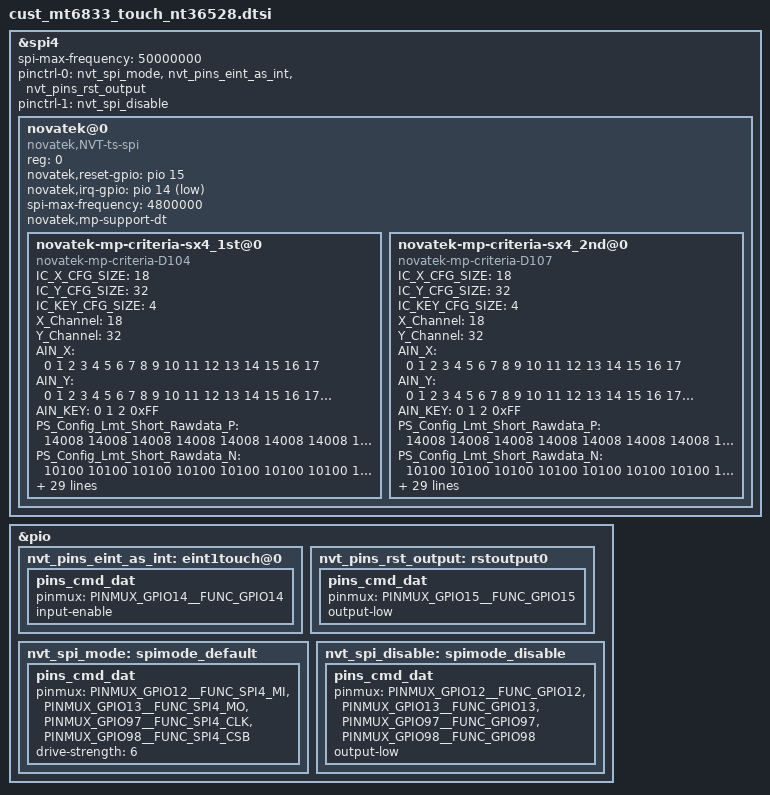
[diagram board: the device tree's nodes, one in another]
&spi4 {
    status = "okay";
	spi-max-frequency = <50000000>;
	pinctrl-names = "nvt_spi_mode", "nvt_spi_disable";
	pinctrl-0 = <&nvt_spi_mode>,<&nvt_pins_eint_as_int>,<&nvt_pins_rst_output>;
	pinctrl-1 = <&nvt_spi_disable>;
	novatek@0 {
        status = "okay";
		compatible = "novatek,NVT-ts-spi";
		reg = <0>; //Same as CS ID
		novatek,reset-gpio = <&pio 15 0x00>;
		novatek,irq-gpio = <&pio 14 0x2001>;	
		spi-max-frequency = <4800000>;	//4800000,9600000,15000000,19200000

		novatek,mp-support-dt;

		novatek-mp-criteria-sx4_1st@0 {
			#address-cells = <1>;
			#size-cells = <0>;
			compatible = "novatek-mp-criteria-D104";

			/* MP Config */
			IC_X_CFG_SIZE = <18>;
			IC_Y_CFG_SIZE = <32>;
			IC_KEY_CFG_SIZE = <4>;
			X_Channel = <18>;
			Y_Channel = <32>;
			AIN_X = <0 1 2 3 4 5 6 7 8 9 10 11 12 13 14 15 16 17>;
			AIN_Y = <0 1 2 3 4 5 6 7 8 9 10 11 12 13 14 15 16 17 18 19 20 21 22 23 24 25 26 27 28 29 30 31>;
			AIN_KEY = <0 1 2 0xFF>;

			/* MP Criteria */
			PS_Config_Lmt_Short_Rawdata_P = <
				14008	14008	14008	14008	14008	14008	14008	14008	14008	14008	14008	14008	14008	14008	14008	14008	14008	14008
				14008	14008	14008	14008	14008	14008	14008	14008	14008	14008	14008	14008	14008	14008	14008	14008	14008	14008
				14008	14008	14008	14008	14008	14008	14008	14008	14008	14008	14008	14008	14008	14008	14008	14008	14008	14008
				14008	14008	14008	14008	14008	14008	14008	14008	14008	14008	14008	14008	14008	14008	14008	14008	14008	14008
				14008	14008	14008	14008	14008	14008	14008	14008	14008	14008	14008	14008	14008	14008	14008	14008	14008	14008
				14008	14008	14008	14008	14008	14008	14008	14008	14008	14008	14008	14008	14008	14008	14008	14008	14008	14008
				14008	14008	14008	14008	14008	14008	14008	14008	14008	14008	14008	14008	14008	14008	14008	14008	14008	14008
				14008	14008	14008	14008	14008	14008	14008	14008	14008	14008	14008	14008	14008	14008	14008	14008	14008	14008
				14008	14008	14008	14008	14008	14008	14008	14008	14008	14008	14008	14008	14008	14008	14008	14008	14008	14008
				14008	14008	14008	14008	14008	14008	14008	14008	14008	14008	14008	14008	14008	14008	14008	14008	14008	14008
				14008	14008	14008	14008	14008	14008	14008	14008	14008	14008	14008	14008	14008	14008	14008	14008	14008	14008
				14008	14008	14008	14008	14008	14008	14008	14008	14008	14008	14008	14008	14008	14008	14008	14008	14008	14008
				14008	14008	14008	14008	14008	14008	14008	14008	14008	14008	14008	14008	14008	14008	14008	14008	14008	14008
				14008	14008	14008	14008	14008	14008	14008	14008	14008	14008	14008	14008	14008	14008	14008	14008	14008	14008
				14008	14008	14008	14008	14008	14008	14008	14008	14008	14008	14008	14008	14008	14008	14008	14008	14008	14008
				14008	14008	14008	14008	14008	14008	14008	14008	14008	14008	14008	14008	14008	14008	14008	14008	14008	14008
				14008	14008	14008	14008	14008	14008	14008	14008	14008	14008	14008	14008	14008	14008	14008	14008	14008	14008
				14008	14008	14008	14008	14008	14008	14008	14008	14008	14008	14008	14008	14008	14008	14008	14008	14008	14008
				14008	14008	14008	14008	14008	14008	14008	14008	14008	14008	14008	14008	14008	14008	14008	14008	14008	14008
				14008	14008	14008	14008	14008	14008	14008	14008	14008	14008	14008	14008	14008	14008	14008	14008	14008	14008
				14008	14008	14008	14008	14008	14008	14008	14008	14008	14008	14008	14008	14008	14008	14008	14008	14008	14008
				14008	14008	14008	14008	14008	14008	14008	14008	14008	14008	14008	14008	14008	14008	14008	14008	14008	14008
				14008	14008	14008	14008	14008	14008	14008	14008	14008	14008	14008	14008	14008	14008	14008	14008	14008	14008
				14008	14008	14008	14008	14008	14008	14008	14008	14008	14008	14008	14008	14008	14008	14008	14008	14008	14008
				14008	14008	14008	14008	14008	14008	14008	14008	14008	14008	14008	14008	14008	14008	14008	14008	14008	14008
				14008	14008	14008	14008	14008	14008	14008	14008	14008	14008	14008	14008	14008	14008	14008	14008	14008	14008
				14008	14008	14008	14008	14008	14008	14008	14008	14008	14008	14008	14008	14008	14008	14008	14008	14008	14008
				14008	14008	14008	14008	14008	14008	14008	14008	14008	14008	14008	14008	14008	14008	14008	14008	14008	14008
				14008	14008	14008	14008	14008	14008	14008	14008	14008	14008	14008	14008	14008	14008	14008	14008	14008	14008
				14008	14008	14008	14008	14008	14008	14008	14008	14008	14008	14008	14008	14008	14008	14008	14008	14008	14008
				14008	14008	14008	14008	14008	14008	14008	14008	14008	14008	14008	14008	14008	14008	14008	14008	14008	14008
				14008	14008	14008	14008	14008	14008	14008	14008	14008	14008	14008	14008	14008	14008	14008	14008	14008	14008
				>;

			PS_Config_Lmt_Short_Rawdata_N = <
				10100	10100	10100	10100	10100	10100	10100	10100	10100	10100	10100	10100	10100	10100	10100	10100	10100	10100
				10100	10100	10100	10100	10100	10100	10100	10100	10100	10100	10100	10100	10100	10100	10100	10100	10100	10100
				10100	10100	10100	10100	10100	10100	10100	10100	10100	10100	10100	10100	10100	10100	10100	10100	10100	10100
				10100	10100	10100	10100	10100	10100	10100	10100	10100	10100	10100	10100	10100	10100	10100	10100	10100	10100
				10100	10100	10100	10100	10100	10100	10100	10100	10100	10100	10100	10100	10100	10100	10100	10100	10100	10100
				10100	10100	10100	10100	10100	10100	10100	10100	10100	10100	10100	10100	10100	10100	10100	10100	10100	10100
				10100	10100	10100	10100	10100	10100	10100	10100	10100	10100	10100	10100	10100	10100	10100	10100	10100	10100
				10100	10100	10100	10100	10100	10100	10100	10100	10100	10100	10100	10100	10100	10100	10100	10100	10100	10100
				10100	10100	10100	10100	10100	10100	10100	10100	10100	10100	10100	10100	10100	10100	10100	10100	10100	10100
				10100	10100	10100	10100	10100	10100	10100	10100	10100	10100	10100	10100	10100	10100	10100	10100	10100	10100
				10100	10100	10100	10100	10100	10100	10100	10100	10100	10100	10100	10100	10100	10100	10100	10100	10100	10100
				10100	10100	10100	10100	10100	10100	10100	10100	10100	10100	10100	10100	10100	10100	10100	10100	10100	10100
				10100	10100	10100	10100	10100	10100	10100	10100	10100	10100	10100	10100	10100	10100	10100	10100	10100	10100
				10100	10100	10100	10100	10100	10100	10100	10100	10100	10100	10100	10100	10100	10100	10100	10100	10100	10100
				10100	10100	10100	10100	10100	10100	10100	10100	10100	10100	10100	10100	10100	10100	10100	10100	10100	10100
				10100	10100	10100	10100	10100	10100	10100	10100	10100	10100	10100	10100	10100	10100	10100	10100	10100	10100
				10100	10100	10100	10100	10100	10100	10100	10100	10100	10100	10100	10100	10100	10100	10100	10100	10100	10100
				10100	10100	10100	10100	10100	10100	10100	10100	10100	10100	10100	10100	10100	10100	10100	10100	10100	10100
				10100	10100	10100	10100	10100	10100	10100	10100	10100	10100	10100	10100	10100	10100	10100	10100	10100	10100
				10100	10100	10100	10100	10100	10100	10100	10100	10100	10100	10100	10100	10100	10100	10100	10100	10100	10100
				10100	10100	10100	10100	10100	10100	10100	10100	10100	10100	10100	10100	10100	10100	10100	10100	10100	10100
				10100	10100	10100	10100	10100	10100	10100	10100	10100	10100	10100	10100	10100	10100	10100	10100	10100	10100
				10100	10100	10100	10100	10100	10100	10100	10100	10100	10100	10100	10100	10100	10100	10100	10100	10100	10100
				10100	10100	10100	10100	10100	10100	10100	10100	10100	10100	10100	10100	10100	10100	10100	10100	10100	10100
				10100	10100	10100	10100	10100	10100	10100	10100	10100	10100	10100	10100	10100	10100	10100	10100	10100	10100
				10100	10100	10100	10100	10100	10100	10100	10100	10100	10100	10100	10100	10100	10100	10100	10100	10100	10100
				10100	10100	10100	10100	10100	10100	10100	10100	10100	10100	10100	10100	10100	10100	10100	10100	10100	10100
				10100	10100	10100	10100	10100	10100	10100	10100	10100	10100	10100	10100	10100	10100	10100	10100	10100	10100
				10100	10100	10100	10100	10100	10100	10100	10100	10100	10100	10100	10100	10100	10100	10100	10100	10100	10100
				10100	10100	10100	10100	10100	10100	10100	10100	10100	10100	10100	10100	10100	10100	10100	10100	10100	10100
				10100	10100	10100	10100	10100	10100	10100	10100	10100	10100	10100	10100	10100	10100	10100	10100	10100	10100
				10100	10100	10100	10100	10100	10100	10100	10100	10100	10100	10100	10100	10100	10100	10100	10100	10100	10100
				>;

			PS_Config_Lmt_Open_Rawdata_P = <
				2667	2643	2563	2510	2446	2381	2345	2269	65535	65535	2043	2113	2132	2184	2230	2248	2302	2356
				2559	2566	2510	2444	2384	2334	2292	2260	2223	2297	2320	2344	2373	2411	2449	2482	2531	2579
				2765	2776	2722	2659	2597	2541	2499	2465	2432	2178	2197	2215	2248	2288	2318	2352	2394	2439
				2600	2625	2572	2507	2446	2394	2352	2318	2289	2342	2360	2383	2418	2456	2492	2530	2575	2618
				2747	2783	2723	2659	2593	2535	2493	2454	2426	2274	2293	2309	2342	2380	2414	2449	2493	2535
				2654	2701	2640	2575	2512	2457	2412	2376	2348	2449	2467	2486	2523	2562	2600	2639	2685	2726
				2773	2740	2694	2638	2568	2507	2475	2432	2393	2302	2327	2356	2379	2426	2465	2492	2533	2482
				2645	2604	2565	2509	2442	2381	2351	2310	2275	2481	2506	2538	2562	2611	2656	2684	2722	2689
				2836	2793	2748	2692	2622	2559	2531	2484	2449	2419	2444	2471	2496	2540	2583	2612	2650	2621
				2709	2663	2621	2565	2498	2437	2407	2363	2331	2541	2566	2597	2622	2667	2712	2747	2782	2768
				2943	2892	2843	2790	2723	2661	2625	2583	2548	2451	2474	2503	2521	2568	2614	2638	2680	2674
				2811	2759	2715	2659	2591	2534	2500	2461	2423	2705	2731	2764	2786	2831	2878	2906	2950	2954
				3031	2976	2927	2867	2803	2740	2702	2664	2619	2570	2591	2625	2643	2692	2736	2758	2801	2814
				2915	2867	2817	2755	2692	2632	2596	2559	2517	2674	2702	2731	2755	2803	2846	2874	2920	2941
				3140	3087	3030	2974	2905	2839	2806	2758	2719	2590	2619	2645	2673	2716	2757	2783	2829	2862
				3011	2960	2908	2849	2780	2722	2685	2643	2605	2766	2793	2821	2852	2895	2939	2975	3017	3058
				3240	3186	3129	3074	3004	2939	2902	2853	2818	2708	2736	2765	2790	2836	2877	2908	2954	3002
				3105	3053	2999	2939	2870	2810	2772	2724	2689	2848	2874	2908	2937	2982	3028	3062	3105	3153
				3342	3297	3241	3177	3109	3046	3002	2960	2915	2757	2775	2813	2835	2883	2927	2955	3000	3045
				3227	3177	3123	3059	2990	2934	2891	2853	2810	2948	2976	3007	3038	3083	3132	3161	3213	3269
				3455	3405	3345	3283	3207	3147	3102	3058	3009	2887	2915	2944	2975	3023	3066	3094	3144	3200
				3331	3282	3228	3161	3090	3024	2985	2939	2895	3083	3112	3146	3174	3227	3273	3310	3354	3406
				3587	3539	3476	3413	3338	3273	3231	3179	3137	2983	3020	3048	3079	3123	3167	3202	3252	3305
				3462	3416	3354	3290	3219	3156	3111	3065	3024	3172	3203	3234	3269	3315	3360	3402	3450	3503
				3706	3661	3594	3529	3455	3388	3343	3293	3251	3090	3116	3150	3178	3224	3275	3307	3364	3409
				3560	3522	3459	3391	3321	3258	3210	3168	3121	3275	3308	3339	3375	3422	3471	3507	3562	3612
				3662	3749	3678	3608	3536	3476	3427	3382	3333	3182	3207	3240	3275	3321	3364	3399	3459	3408
				3601	3693	3632	3560	3485	3426	3381	3332	3290	3378	3403	3443	3476	3522	3573	3612	3664	3588
				3825	3940	3870	3802	3727	3658	3615	3564	3517	3298	3328	3357	3394	3441	3486	3522	3580	3508
				3611	3735	3676	3604	3534	3469	3424	3373	3332	3483	3508	3546	3585	3634	3681	3724	3772	3678
				3840	3994	3930	3858	3787	3717	3669	3619	3574	3385	3412	3447	3479	3528	3577	3616	3669	3574
				3832	3903	3895	3822	3752	3688	3636	3588	3535	3564	3598	3634	3675	3721	3772	3809	3811	3786
				>;

			PS_Config_Lmt_Open_Rawdata_N = <
				1143	1133	1099	1076	1048	1021	1005	973	(-65535)	(-65535)	875	905	914	936	956	964	986	1010
				1097	1100	1076	1048	1022	1000	982	968	953	985	994	1004	1017	1033	1049	1064	1085	1105
				1185	1190	1166	1139	1113	1089	1071	1057	1042	934	941	949	964	980	994	1008	1026	1045
				1114	1125	1102	1075	1048	1026	1008	994	981	1004	1012	1021	1036	1052	1068	1084	1103	1122
				1177	1193	1167	1139	1111	1087	1069	1052	1040	974	983	989	1004	1020	1034	1049	1069	1087
				1138	1157	1132	1103	1076	1053	1034	1018	1006	1049	1057	1066	1081	1098	1114	1131	1151	1168
				1189	1174	1154	1130	1100	1075	1061	1042	1025	986	997	1010	1019	1040	1057	1068	1085	1064
				1133	1116	1099	1075	1046	1021	1007	990	975	1063	1074	1088	1098	1119	1138	1150	1166	1153
				1216	1197	1178	1154	1124	1097	1085	1064	1049	1037	1048	1059	1070	1088	1107	1120	1136	1123
				1161	1141	1123	1099	1070	1045	1031	1013	999	1089	1100	1113	1124	1143	1162	1177	1192	1186
				1261	1240	1219	1196	1167	1141	1125	1107	1092	1051	1060	1073	1081	1100	1120	1130	1148	1146
				1205	1183	1163	1139	1111	1086	1072	1055	1039	1159	1171	1184	1194	1213	1234	1246	1264	1266
				1299	1276	1255	1229	1201	1174	1158	1142	1123	1102	1111	1125	1133	1154	1172	1182	1201	1206
				1249	1229	1207	1181	1154	1128	1112	1097	1079	1146	1158	1171	1181	1201	1220	1232	1252	1261
				1346	1323	1298	1274	1245	1217	1202	1182	1165	1110	1123	1133	1145	1164	1181	1193	1213	1226
				1291	1268	1246	1221	1192	1166	1151	1133	1117	1186	1197	1209	1222	1241	1259	1275	1293	1310
				1388	1366	1341	1318	1288	1259	1244	1223	1208	1160	1172	1185	1196	1216	1233	1246	1266	1286
				1331	1309	1285	1259	1230	1204	1188	1168	1153	1220	1232	1246	1259	1278	1298	1312	1331	1351
				1432	1413	1389	1361	1333	1306	1286	1268	1249	1181	1189	1205	1215	1235	1255	1267	1286	1305
				1383	1361	1339	1311	1282	1258	1239	1223	1204	1264	1276	1289	1302	1321	1342	1355	1377	1401
				1481	1459	1433	1407	1375	1349	1330	1310	1289	1237	1249	1262	1275	1295	1314	1326	1348	1372
				1427	1406	1384	1355	1324	1296	1279	1259	1241	1321	1334	1348	1360	1383	1403	1418	1438	1460
				1537	1517	1490	1463	1430	1403	1385	1363	1345	1279	1294	1306	1319	1339	1357	1372	1394	1417
				1484	1464	1438	1410	1379	1352	1333	1313	1296	1360	1373	1386	1401	1421	1440	1458	1478	1501
				1588	1569	1540	1513	1481	1452	1433	1411	1393	1324	1336	1350	1362	1382	1403	1417	1442	1461
				1526	1510	1483	1453	1423	1396	1376	1358	1337	1403	1418	1431	1447	1466	1487	1503	1526	1548
				1570	1607	1576	1546	1516	1490	1469	1450	1429	1364	1375	1388	1403	1423	1442	1457	1483	1460
				1543	1583	1556	1526	1493	1468	1449	1428	1410	1448	1459	1475	1490	1510	1531	1548	1570	1538
				1639	1688	1658	1630	1597	1568	1549	1528	1507	1414	1426	1439	1454	1475	1494	1510	1534	1504
				1547	1601	1576	1544	1514	1487	1468	1445	1428	1493	1504	1520	1537	1558	1577	1596	1616	1576
				1646	1712	1684	1654	1623	1593	1573	1551	1532	1451	1462	1477	1491	1512	1533	1550	1573	1532
				1642	1673	1669	1638	1608	1580	1558	1538	1515	1528	1542	1558	1575	1595	1616	1633	1633	1622
				>;

			PS_Config_Lmt_FW_Rawdata_P = <
				1119	1123	1121	1121	1121	1119	1123	1120	65535	65535	1123	1123	1121	1121	1120	1120	1120	1121
				1123	1121	1121	1121	1120	1117	1121	1120	1124	1121	1120	1120	1120	1120	1119	1119	1120	1120
				1123	1120	1124	1119	1124	1121	1121	1121	1120	1121	1121	1120	1121	1120	1121	1120	1123	1121
				1123	1121	1120	1121	1124	1123	1123	1123	1119	1123	1124	1123	1121	1124	1120	1121	1121	1121
				1120	1121	1121	1123	1120	1121	1120	1120	1119	1124	1124	1123	1119	1123	1119	1124	1121	1121
				1123	1120	1120	1121	1123	1121	1121	1121	1120	1119	1120	1120	1123	1126	1124	1123	1120	1123
				1121	1121	1121	1121	1123	1120	1123	1121	1120	1121	1121	1121	1120	1121	1121	1120	1121	1123
				1123	1120	1124	1120	1123	1124	1123	1123	1117	1117	1124	1123	1124	1126	1121	1120	1121	1124
				1124	1120	1121	1123	1121	1123	1120	1123	1124	1123	1121	1121	1121	1121	1120	1121	1120	1121
				1121	1120	1123	1121	1123	1120	1121	1121	1120	1120	1121	1124	1123	1127	1123	1124	1121	1123
				1121	1119	1121	1123	1121	1121	1123	1120	1119	1120	1121	1119	1120	1120	1123	1121	1121	1121
				1123	1123	1120	1123	1121	1121	1123	1121	1121	1121	1121	1120	1119	1120	1117	1121	1121	1121
				1121	1120	1121	1121	1120	1120	1121	1123	1121	1123	1121	1123	1121	1123	1123	1123	1121	1123
				1124	1123	1123	1123	1121	1121	1123	1121	1123	1119	1121	1123	1124	1124	1124	1119	1121	1121
				1120	1119	1121	1121	1120	1120	1123	1124	1121	1121	1121	1124	1121	1123	1121	1123	1123	1121
				1121	1120	1123	1120	1121	1120	1123	1123	1120	1121	1121	1121	1120	1121	1121	1123	1121	1123
				1123	1123	1120	1121	1121	1120	1123	1123	1120	1123	1120	1121	1121	1123	1120	1121	1120	1120
				1120	1121	1121	1124	1121	1121	1121	1124	1120	1119	1123	1123	1123	1127	1127	1120	1123	1123
				1121	1123	1119	1123	1124	1123	1124	1121	1120	1119	1124	1120	1121	1123	1123	1121	1124	1119
				1121	1123	1120	1123	1124	1123	1123	1123	1121	1120	1123	1120	1121	1126	1126	1121	1123	1121
				1119	1123	1121	1120	1121	1120	1121	1120	1120	1121	1120	1120	1120	1121	1119	1123	1119	1121
				1121	1121	1121	1121	1123	1121	1121	1121	1123	1123	1123	1121	1121	1123	1123	1120	1123	1120
				1121	1123	1121	1123	1124	1121	1124	1123	1121	1119	1123	1120	1121	1121	1121	1121	1123	1124
				1121	1121	1123	1121	1121	1120	1120	1119	1120	1119	1120	1120	1119	1120	1119	1120	1119	1120
				1126	1123	1121	1121	1121	1119	1120	1121	1121	1121	1121	1121	1121	1123	1123	1119	1123	1124
				1120	1121	1120	1121	1121	1120	1121	1120	1120	1120	1124	1120	1120	1121	1121	1120	1120	1123
				1120	1123	1124	1121	1121	1120	1120	1121	1121	1120	1123	1120	1120	1121	1124	1126	1120	1121
				1123	1123	1120	1121	1123	1121	1121	1121	1121	1123	1123	1124	1121	1124	1121	1123	1120	1121
				1120	1117	1123	1124	1123	1121	1120	1121	1121	1121	1121	1121	1121	1123	1121	1120	1119	1126
				1124	1121	1123	1121	1123	1123	1121	1123	1123	1120	1121	1120	1120	1121	1121	1121	1120	1123
				1121	1120	1120	1121	1120	1120	1121	1120	1121	1120	1120	1120	1120	1123	1121	1121	1124	1121
				1120	1123	1123	1121	1124	1123	1123	1121	1123	1124	1120	1120	1120	1121	1120	1121	1119	1120
				>;

			PS_Config_Lmt_FW_Rawdata_N = <
				479	481	481	481	481	479	481	480	(-65535)	(-65535)	481	481	481	481	480	480	480	481
				481	481	481	481	480	479	481	480	482	481	480	480	480	480	479	479	480	480
				481	480	482	479	482	481	481	481	480	481	481	480	481	480	481	480	481	481
				481	481	480	481	482	481	481	481	479	481	482	481	481	482	480	481	481	481
				480	481	481	481	480	481	480	480	479	482	482	481	479	481	479	482	481	481
				481	480	480	481	481	481	481	481	480	479	480	480	481	482	482	481	480	481
				481	481	481	481	481	480	481	481	480	481	481	481	480	481	481	480	481	481
				481	480	482	480	481	482	481	481	479	479	482	481	482	482	481	480	481	482
				482	480	481	481	481	481	480	481	482	481	481	481	481	481	480	481	480	481
				481	480	481	481	481	480	481	481	480	480	481	482	481	483	481	482	481	481
				481	479	481	481	481	481	481	480	479	480	481	479	480	480	481	481	481	481
				481	481	480	481	481	481	481	481	481	481	481	480	479	480	479	481	481	481
				481	480	481	481	480	480	481	481	481	481	481	481	481	481	481	481	481	481
				482	481	481	481	481	481	481	481	481	479	481	481	482	482	482	479	481	481
				480	479	481	481	480	480	481	482	481	481	481	482	481	481	481	481	481	481
				481	480	481	480	481	480	481	481	480	481	481	481	480	481	481	481	481	481
				481	481	480	481	481	480	481	481	480	481	480	481	481	481	480	481	480	480
				480	481	481	482	481	481	481	482	480	479	481	481	481	483	483	480	481	481
				481	481	479	481	482	481	482	481	480	479	482	480	481	481	481	481	482	479
				481	481	480	481	482	481	481	481	481	480	481	480	481	482	482	481	481	481
				479	481	481	480	481	480	481	480	480	481	480	480	480	481	479	481	479	481
				481	481	481	481	481	481	481	481	481	481	481	481	481	481	481	480	481	480
				481	481	481	481	482	481	482	481	481	479	481	480	481	481	481	481	481	482
				481	481	481	481	481	480	480	479	480	479	480	480	479	480	479	480	479	480
				482	481	481	481	481	479	480	481	481	481	481	481	481	481	481	479	481	482
				480	481	480	481	481	480	481	480	480	480	482	480	480	481	481	480	480	481
				480	481	482	481	481	480	480	481	481	480	481	480	480	481	482	482	480	481
				481	481	480	481	481	481	481	481	481	481	481	482	481	482	481	481	480	481
				480	479	481	482	481	481	480	481	481	481	481	481	481	481	481	480	479	482
				482	481	481	481	481	481	481	481	481	480	481	480	480	481	481	481	480	481
				481	480	480	481	480	480	481	480	481	480	480	480	480	481	481	481	482	481
				480	481	481	481	482	481	481	481	481	482	480	480	480	481	480	481	479	480
				>;

			PS_Config_Lmt_FW_CC_P = <
				142	137	131	131	131	132	134	127	65535	65535	126	131	131	128	128	128	135	141
				152	146	141	138	138	138	138	138	139	138	137	137	137	137	137	139	146	150
				152	148	141	138	138	138	138	138	139	139	138	138	138	138	138	141	146	153
				153	146	141	138	138	138	138	138	141	141	138	138	138	138	138	142	148	153
				152	148	142	139	139	139	139	139	142	142	139	139	139	139	139	142	148	153
				155	149	144	142	141	141	141	141	144	144	141	141	141	141	141	144	149	156
				155	148	144	138	137	137	137	137	138	139	138	138	138	138	138	145	150	155
				155	148	142	137	137	135	135	137	137	138	137	137	137	137	138	144	149	155
				155	148	144	137	137	137	137	137	138	139	138	138	138	138	138	145	149	156
				155	148	144	137	137	137	137	137	138	137	137	137	135	137	137	142	148	153
				157	149	144	138	137	137	138	138	138	138	138	138	137	138	138	144	149	156
				155	148	142	137	137	137	137	138	138	141	141	139	139	139	139	145	150	157
				156	148	144	138	138	138	138	138	139	142	141	141	139	139	141	145	150	157
				156	149	144	138	138	138	138	139	139	141	139	139	138	138	138	144	149	156
				157	150	144	139	139	139	139	139	141	141	139	139	139	139	139	144	150	157
				156	149	144	139	139	139	139	139	141	141	139	139	139	139	139	144	149	156
				157	150	145	141	141	141	141	141	142	144	144	142	142	142	142	146	153	160
				157	150	145	141	141	139	141	141	142	144	142	141	141	141	142	145	152	159
				157	152	145	142	142	142	142	142	144	144	144	144	144	144	144	146	153	159
				159	152	145	142	142	142	142	142	144	144	144	142	142	142	144	146	153	160
				160	153	146	144	144	144	144	144	145	145	144	144	144	144	144	148	155	160
				161	155	148	144	144	144	144	144	145	145	144	144	144	144	144	148	155	160
				163	157	150	146	146	146	146	146	148	148	146	148	146	146	146	150	157	163
				164	157	149	146	146	146	146	146	148	148	146	146	146	146	146	150	157	164
				164	157	152	148	148	148	148	148	149	149	148	148	148	148	148	152	159	166
				166	159	152	149	148	148	148	148	150	149	148	148	148	148	148	152	157	164
				161	159	152	149	148	148	148	149	150	149	148	148	148	148	148	152	159	161
				161	159	152	149	148	148	148	149	150	150	148	148	149	148	149	152	159	161
				164	159	153	149	149	149	149	149	152	150	149	149	149	149	149	152	159	163
				160	157	150	148	148	148	148	148	149	150	148	148	148	148	149	152	159	161
				161	159	152	149	148	148	148	148	149	150	148	148	149	148	149	152	159	163
				163	159	153	150	149	149	149	149	152	150	148	148	149	149	149	152	159	163
				>;

			PS_Config_Lmt_FW_CC_N = <
				64	61	59	59	59	60	60	57	(-65535)	(-65535)	56	59	59	58	58	58	61	63
				68	66	63	62	62	62	62	62	63	62	61	61	61	61	61	63	66	68
				68	66	63	62	62	62	62	62	63	63	62	62	62	62	62	63	66	69
				69	66	63	62	62	62	62	62	63	63	62	62	62	62	62	64	66	69
				68	66	64	63	63	63	63	63	64	64	63	63	63	63	63	64	66	69
				69	67	64	64	63	63	63	63	64	64	63	63	63	63	63	64	67	70
				69	66	64	62	61	61	61	61	62	63	62	62	62	62	62	65	68	69
				69	66	64	61	61	61	61	61	61	62	61	61	61	61	62	64	67	69
				69	66	64	61	61	61	61	61	62	63	62	62	62	62	62	65	67	70
				69	66	64	61	61	61	61	61	62	61	61	61	61	61	61	64	66	69
				71	67	64	62	61	61	62	62	62	62	62	62	61	62	62	64	67	70
				69	66	64	61	61	61	61	62	62	63	63	63	63	63	63	65	68	71
				70	66	64	62	62	62	62	62	63	64	63	63	63	63	63	65	68	71
				70	67	64	62	62	62	62	63	63	63	63	63	62	62	62	64	67	70
				71	68	64	63	63	63	63	63	63	63	63	63	63	63	63	64	68	71
				70	67	64	63	63	63	63	63	63	63	63	63	63	63	63	64	67	70
				71	68	65	63	63	63	63	63	64	64	64	64	64	64	64	66	69	72
				71	68	65	63	63	63	63	63	64	64	64	63	63	63	64	65	68	71
				71	68	65	64	64	64	64	64	64	64	64	64	64	64	64	66	69	71
				71	68	65	64	64	64	64	64	64	64	64	64	64	64	64	66	69	72
				72	69	66	64	64	64	64	64	65	65	64	64	64	64	64	66	69	72
				73	69	66	64	64	64	64	64	65	65	64	64	64	64	64	66	69	72
				73	71	68	66	66	66	66	66	66	66	66	66	66	66	66	68	71	73
				74	71	67	66	66	66	66	66	66	66	66	66	66	66	66	68	71	74
				74	71	68	66	66	66	66	66	67	67	66	66	66	66	66	68	71	74
				74	71	68	67	66	66	66	66	68	67	66	66	66	66	66	68	71	74
				73	71	68	67	66	66	66	67	68	67	66	66	66	66	66	68	71	73
				73	71	68	67	66	66	66	67	68	68	66	66	67	66	67	68	71	73
				74	71	69	67	67	67	67	67	68	68	67	67	67	67	67	68	71	73
				72	71	68	66	66	66	66	66	67	68	66	66	66	66	67	68	71	73
				73	71	68	67	66	66	66	66	67	68	66	66	67	66	67	68	71	73
				73	71	69	68	67	67	67	67	68	68	66	66	67	67	67	68	71	73
				>;

			PS_Config_Lmt_FW_Diff_P = <
				50	50	50	50	50	50	50	50	65535	65535	50	50	50	50	50	50	50	50
				50	50	50	50	50	50	50	50	50	50	50	50	50	50	50	50	50	50
				50	50	50	50	50	50	50	50	50	50	50	50	50	50	50	50	50	50
				50	50	50	50	50	50	50	50	50	50	50	50	50	50	50	50	50	50
				50	50	50	50	50	50	50	50	50	50	50	50	50	50	50	50	50	50
				50	50	50	50	50	50	50	50	50	50	50	50	50	50	50	50	50	50
				50	50	50	50	50	50	50	50	50	50	50	50	50	50	50	50	50	50
				50	50	50	50	50	50	50	50	50	50	50	50	50	50	50	50	50	50
				50	50	50	50	50	50	50	50	50	50	50	50	50	50	50	50	50	50
				50	50	50	50	50	50	50	50	50	50	50	50	50	50	50	50	50	50
				50	50	50	50	50	50	50	50	50	50	50	50	50	50	50	50	50	50
				50	50	50	50	50	50	50	50	50	50	50	50	50	50	50	50	50	50
				50	50	50	50	50	50	50	50	50	50	50	50	50	50	50	50	50	50
				50	50	50	50	50	50	50	50	50	50	50	50	50	50	50	50	50	50
				50	50	50	50	50	50	50	50	50	50	50	50	50	50	50	50	50	50
				50	50	50	50	50	50	50	50	50	50	50	50	50	50	50	50	50	50
				50	50	50	50	50	50	50	50	50	50	50	50	50	50	50	50	50	50
				50	50	50	50	50	50	50	50	50	50	50	50	50	50	50	50	50	50
				50	50	50	50	50	50	50	50	50	50	50	50	50	50	50	50	50	50
				50	50	50	50	50	50	50	50	50	50	50	50	50	50	50	50	50	50
				50	50	50	50	50	50	50	50	50	50	50	50	50	50	50	50	50	50
				50	50	50	50	50	50	50	50	50	50	50	50	50	50	50	50	50	50
				50	50	50	50	50	50	50	50	50	50	50	50	50	50	50	50	50	50
				50	50	50	50	50	50	50	50	50	50	50	50	50	50	50	50	50	50
				50	50	50	50	50	50	50	50	50	50	50	50	50	50	50	50	50	50
				50	50	50	50	50	50	50	50	50	50	50	50	50	50	50	50	50	50
				50	50	50	50	50	50	50	50	50	50	50	50	50	50	50	50	50	50
				50	50	50	50	50	50	50	50	50	50	50	50	50	50	50	50	50	50
				50	50	50	50	50	50	50	50	50	50	50	50	50	50	50	50	50	50
				50	50	50	50	50	50	50	50	50	50	50	50	50	50	50	50	50	50
				50	50	50	50	50	50	50	50	50	50	50	50	50	50	50	50	50	50
				50	50	50	50	50	50	50	50	50	50	50	50	50	50	50	50	50	50
				>;

			PS_Config_Lmt_FW_Diff_N = <
				(-50)	(-50)	(-50)	(-50)	(-50)	(-50)	(-50)	(-50)	(-65535)	(-65535)	(-50)	(-50)	(-50)	(-50)	(-50)	(-50)	(-50)	(-50)
				(-50)	(-50)	(-50)	(-50)	(-50)	(-50)	(-50)	(-50)	(-50)	(-50)	(-50)	(-50)	(-50)	(-50)	(-50)	(-50)	(-50)	(-50)
				(-50)	(-50)	(-50)	(-50)	(-50)	(-50)	(-50)	(-50)	(-50)	(-50)	(-50)	(-50)	(-50)	(-50)	(-50)	(-50)	(-50)	(-50)
				(-50)	(-50)	(-50)	(-50)	(-50)	(-50)	(-50)	(-50)	(-50)	(-50)	(-50)	(-50)	(-50)	(-50)	(-50)	(-50)	(-50)	(-50)
				(-50)	(-50)	(-50)	(-50)	(-50)	(-50)	(-50)	(-50)	(-50)	(-50)	(-50)	(-50)	(-50)	(-50)	(-50)	(-50)	(-50)	(-50)
				(-50)	(-50)	(-50)	(-50)	(-50)	(-50)	(-50)	(-50)	(-50)	(-50)	(-50)	(-50)	(-50)	(-50)	(-50)	(-50)	(-50)	(-50)
				(-50)	(-50)	(-50)	(-50)	(-50)	(-50)	(-50)	(-50)	(-50)	(-50)	(-50)	(-50)	(-50)	(-50)	(-50)	(-50)	(-50)	(-50)
				(-50)	(-50)	(-50)	(-50)	(-50)	(-50)	(-50)	(-50)	(-50)	(-50)	(-50)	(-50)	(-50)	(-50)	(-50)	(-50)	(-50)	(-50)
				(-50)	(-50)	(-50)	(-50)	(-50)	(-50)	(-50)	(-50)	(-50)	(-50)	(-50)	(-50)	(-50)	(-50)	(-50)	(-50)	(-50)	(-50)
				(-50)	(-50)	(-50)	(-50)	(-50)	(-50)	(-50)	(-50)	(-50)	(-50)	(-50)	(-50)	(-50)	(-50)	(-50)	(-50)	(-50)	(-50)
				(-50)	(-50)	(-50)	(-50)	(-50)	(-50)	(-50)	(-50)	(-50)	(-50)	(-50)	(-50)	(-50)	(-50)	(-50)	(-50)	(-50)	(-50)
				(-50)	(-50)	(-50)	(-50)	(-50)	(-50)	(-50)	(-50)	(-50)	(-50)	(-50)	(-50)	(-50)	(-50)	(-50)	(-50)	(-50)	(-50)
				(-50)	(-50)	(-50)	(-50)	(-50)	(-50)	(-50)	(-50)	(-50)	(-50)	(-50)	(-50)	(-50)	(-50)	(-50)	(-50)	(-50)	(-50)
				(-50)	(-50)	(-50)	(-50)	(-50)	(-50)	(-50)	(-50)	(-50)	(-50)	(-50)	(-50)	(-50)	(-50)	(-50)	(-50)	(-50)	(-50)
				(-50)	(-50)	(-50)	(-50)	(-50)	(-50)	(-50)	(-50)	(-50)	(-50)	(-50)	(-50)	(-50)	(-50)	(-50)	(-50)	(-50)	(-50)
				(-50)	(-50)	(-50)	(-50)	(-50)	(-50)	(-50)	(-50)	(-50)	(-50)	(-50)	(-50)	(-50)	(-50)	(-50)	(-50)	(-50)	(-50)
				(-50)	(-50)	(-50)	(-50)	(-50)	(-50)	(-50)	(-50)	(-50)	(-50)	(-50)	(-50)	(-50)	(-50)	(-50)	(-50)	(-50)	(-50)
				(-50)	(-50)	(-50)	(-50)	(-50)	(-50)	(-50)	(-50)	(-50)	(-50)	(-50)	(-50)	(-50)	(-50)	(-50)	(-50)	(-50)	(-50)
				(-50)	(-50)	(-50)	(-50)	(-50)	(-50)	(-50)	(-50)	(-50)	(-50)	(-50)	(-50)	(-50)	(-50)	(-50)	(-50)	(-50)	(-50)
				(-50)	(-50)	(-50)	(-50)	(-50)	(-50)	(-50)	(-50)	(-50)	(-50)	(-50)	(-50)	(-50)	(-50)	(-50)	(-50)	(-50)	(-50)
				(-50)	(-50)	(-50)	(-50)	(-50)	(-50)	(-50)	(-50)	(-50)	(-50)	(-50)	(-50)	(-50)	(-50)	(-50)	(-50)	(-50)	(-50)
				(-50)	(-50)	(-50)	(-50)	(-50)	(-50)	(-50)	(-50)	(-50)	(-50)	(-50)	(-50)	(-50)	(-50)	(-50)	(-50)	(-50)	(-50)
				(-50)	(-50)	(-50)	(-50)	(-50)	(-50)	(-50)	(-50)	(-50)	(-50)	(-50)	(-50)	(-50)	(-50)	(-50)	(-50)	(-50)	(-50)
				(-50)	(-50)	(-50)	(-50)	(-50)	(-50)	(-50)	(-50)	(-50)	(-50)	(-50)	(-50)	(-50)	(-50)	(-50)	(-50)	(-50)	(-50)
				(-50)	(-50)	(-50)	(-50)	(-50)	(-50)	(-50)	(-50)	(-50)	(-50)	(-50)	(-50)	(-50)	(-50)	(-50)	(-50)	(-50)	(-50)
				(-50)	(-50)	(-50)	(-50)	(-50)	(-50)	(-50)	(-50)	(-50)	(-50)	(-50)	(-50)	(-50)	(-50)	(-50)	(-50)	(-50)	(-50)
				(-50)	(-50)	(-50)	(-50)	(-50)	(-50)	(-50)	(-50)	(-50)	(-50)	(-50)	(-50)	(-50)	(-50)	(-50)	(-50)	(-50)	(-50)
				(-50)	(-50)	(-50)	(-50)	(-50)	(-50)	(-50)	(-50)	(-50)	(-50)	(-50)	(-50)	(-50)	(-50)	(-50)	(-50)	(-50)	(-50)
				(-50)	(-50)	(-50)	(-50)	(-50)	(-50)	(-50)	(-50)	(-50)	(-50)	(-50)	(-50)	(-50)	(-50)	(-50)	(-50)	(-50)	(-50)
				(-50)	(-50)	(-50)	(-50)	(-50)	(-50)	(-50)	(-50)	(-50)	(-50)	(-50)	(-50)	(-50)	(-50)	(-50)	(-50)	(-50)	(-50)
				(-50)	(-50)	(-50)	(-50)	(-50)	(-50)	(-50)	(-50)	(-50)	(-50)	(-50)	(-50)	(-50)	(-50)	(-50)	(-50)	(-50)	(-50)
				(-50)	(-50)	(-50)	(-50)	(-50)	(-50)	(-50)	(-50)	(-50)	(-50)	(-50)	(-50)	(-50)	(-50)	(-50)	(-50)	(-50)	(-50)
				>;

			PS_Config_Lmt_Doze_FW_Rawdata_P = <
				820 820
				820 820
				820 820
				820 820
				820 820
				820 820
				820 820
				820 820
				820 820
				820 820
				820 820
				820 820
				820 820
				820 820
				820 820
				820 820
				820 820
				820 820
				820 820
				820 820
				820 820
				820 820
				820 820
				820 820
				820 820
				820 820
				820 820
				820 820
				820 820
				820 820
				820 820
				820 820
				>;

			PS_Config_Lmt_Doze_FW_Rawdata_N = <
				380 380
				380 380
				380 380
				380 380
				380 380
				380 380
				380 380
				380 380
				380 380
				380 380
				380 380
				380 380
				380 380
				380 380
				380 380
				380 380
				380 380
				380 380
				380 380
				380 380
				380 380
				380 380
				380 380
				380 380
				380 380
				380 380
				380 380
				380 380
				380 380
				380 380
				380 380
				380 380
				>;

			PS_Config_Lmt_Doze_FW_CC_P = <
				245 245
				245 245
				245 245
				245 245
				245 245
				245 245
				245 245
				245 245
				245 245
				245 245
				245 245
				245 245
				245 245
				245 245
				245 245
				245 245
				245 245
				245 245
				245 245
				245 245
				245 245
				245 245
				245 245
				245 245
				245 245
				245 245
				245 245
				245 245
				245 245
				245 245
				245 245
				245 245
				>;

			PS_Config_Lmt_Doze_FW_CC_N = <
				0 0
				0 0
				0 0
				0 0
				0 0
				0 0
				0 0
				0 0
				0 0
				0 0
				0 0
				0 0
				0 0
				0 0
				0 0
				0 0
				0 0
				0 0
				0 0
				0 0
				0 0
				0 0
				0 0
				0 0
				0 0
				0 0
				0 0
				0 0
				0 0
				0 0
				0 0
				0 0
				>;

			PS_Config_Lmt_Doze_FW_Diff_P = <
				160 160
				160 160
				160 160
				160 160
				160 160
				160 160
				160 160
				160 160
				160 160
				160 160
				160 160
				160 160
				160 160
				160 160
				160 160
				160 160
				160 160
				160 160
				160 160
				160 160
				160 160
				160 160
				160 160
				160 160
				160 160
				160 160
				160 160
				160 160
				160 160
				160 160
				160 160
				160 160
				>;

			PS_Config_Lmt_Doze_FW_Diff_N = <
				(-160) (-160)
				(-160) (-160)
				(-160) (-160)
				(-160) (-160)
				(-160) (-160)
				(-160) (-160)
				(-160) (-160)
				(-160) (-160)
				(-160) (-160)
				(-160) (-160)
				(-160) (-160)
				(-160) (-160)
				(-160) (-160)
				(-160) (-160)
				(-160) (-160)
				(-160) (-160)
				(-160) (-160)
				(-160) (-160)
				(-160) (-160)
				(-160) (-160)
				(-160) (-160)
				(-160) (-160)
				(-160) (-160)
				(-160) (-160)
				(-160) (-160)
				(-160) (-160)
				(-160) (-160)
				(-160) (-160)
				(-160) (-160)
				(-160) (-160)
				(-160) (-160)
				(-160) (-160)
				>;

			PS_Config_Diff_Test_Frame = <50>;
		};

		novatek-mp-criteria-sx4_2nd@0 {
			#address-cells = <1>;
			#size-cells = <0>;
			compatible = "novatek-mp-criteria-D107";

			/* MP Config */
			IC_X_CFG_SIZE = <18>;
			IC_Y_CFG_SIZE = <32>;
			IC_KEY_CFG_SIZE = <4>;
			X_Channel = <18>;
			Y_Channel = <32>;
			AIN_X = <0 1 2 3 4 5 6 7 8 9 10 11 12 13 14 15 16 17>;
			AIN_Y = <0 1 2 3 4 5 6 7 8 9 10 11 12 13 14 15 16 17 18 19 20 21 22 23 24 25 26 27 28 29 30 31>;
			AIN_KEY = <0 1 2 0xFF>;

			/* MP Criteria */
			PS_Config_Lmt_Short_Rawdata_P = <
				14008	14008	14008	14008	14008	14008	14008	14008	14008	14008	14008	14008	14008	14008	14008	14008	14008	14008
				14008	14008	14008	14008	14008	14008	14008	14008	14008	14008	14008	14008	14008	14008	14008	14008	14008	14008
				14008	14008	14008	14008	14008	14008	14008	14008	14008	14008	14008	14008	14008	14008	14008	14008	14008	14008
				14008	14008	14008	14008	14008	14008	14008	14008	14008	14008	14008	14008	14008	14008	14008	14008	14008	14008
				14008	14008	14008	14008	14008	14008	14008	14008	14008	14008	14008	14008	14008	14008	14008	14008	14008	14008
				14008	14008	14008	14008	14008	14008	14008	14008	14008	14008	14008	14008	14008	14008	14008	14008	14008	14008
				14008	14008	14008	14008	14008	14008	14008	14008	14008	14008	14008	14008	14008	14008	14008	14008	14008	14008
				14008	14008	14008	14008	14008	14008	14008	14008	14008	14008	14008	14008	14008	14008	14008	14008	14008	14008
				14008	14008	14008	14008	14008	14008	14008	14008	14008	14008	14008	14008	14008	14008	14008	14008	14008	14008
				14008	14008	14008	14008	14008	14008	14008	14008	14008	14008	14008	14008	14008	14008	14008	14008	14008	14008
				14008	14008	14008	14008	14008	14008	14008	14008	14008	14008	14008	14008	14008	14008	14008	14008	14008	14008
				14008	14008	14008	14008	14008	14008	14008	14008	14008	14008	14008	14008	14008	14008	14008	14008	14008	14008
				14008	14008	14008	14008	14008	14008	14008	14008	14008	14008	14008	14008	14008	14008	14008	14008	14008	14008
				14008	14008	14008	14008	14008	14008	14008	14008	14008	14008	14008	14008	14008	14008	14008	14008	14008	14008
				14008	14008	14008	14008	14008	14008	14008	14008	14008	14008	14008	14008	14008	14008	14008	14008	14008	14008
				14008	14008	14008	14008	14008	14008	14008	14008	14008	14008	14008	14008	14008	14008	14008	14008	14008	14008
				14008	14008	14008	14008	14008	14008	14008	14008	14008	14008	14008	14008	14008	14008	14008	14008	14008	14008
				14008	14008	14008	14008	14008	14008	14008	14008	14008	14008	14008	14008	14008	14008	14008	14008	14008	14008
				14008	14008	14008	14008	14008	14008	14008	14008	14008	14008	14008	14008	14008	14008	14008	14008	14008	14008
				14008	14008	14008	14008	14008	14008	14008	14008	14008	14008	14008	14008	14008	14008	14008	14008	14008	14008
				14008	14008	14008	14008	14008	14008	14008	14008	14008	14008	14008	14008	14008	14008	14008	14008	14008	14008
				14008	14008	14008	14008	14008	14008	14008	14008	14008	14008	14008	14008	14008	14008	14008	14008	14008	14008
				14008	14008	14008	14008	14008	14008	14008	14008	14008	14008	14008	14008	14008	14008	14008	14008	14008	14008
				14008	14008	14008	14008	14008	14008	14008	14008	14008	14008	14008	14008	14008	14008	14008	14008	14008	14008
				14008	14008	14008	14008	14008	14008	14008	14008	14008	14008	14008	14008	14008	14008	14008	14008	14008	14008
				14008	14008	14008	14008	14008	14008	14008	14008	14008	14008	14008	14008	14008	14008	14008	14008	14008	14008
				14008	14008	14008	14008	14008	14008	14008	14008	14008	14008	14008	14008	14008	14008	14008	14008	14008	14008
				14008	14008	14008	14008	14008	14008	14008	14008	14008	14008	14008	14008	14008	14008	14008	14008	14008	14008
				14008	14008	14008	14008	14008	14008	14008	14008	14008	14008	14008	14008	14008	14008	14008	14008	14008	14008
				14008	14008	14008	14008	14008	14008	14008	14008	14008	14008	14008	14008	14008	14008	14008	14008	14008	14008
				14008	14008	14008	14008	14008	14008	14008	14008	14008	14008	14008	14008	14008	14008	14008	14008	14008	14008
				14008	14008	14008	14008	14008	14008	14008	14008	14008	14008	14008	14008	14008	14008	14008	14008	14008	14008
				>;

			PS_Config_Lmt_Short_Rawdata_N = <
				10100	10100	10100	10100	10100	10100	10100	10100	10100	10100	10100	10100	10100	10100	10100	10100	10100	10100
				10100	10100	10100	10100	10100	10100	10100	10100	10100	10100	10100	10100	10100	10100	10100	10100	10100	10100
				10100	10100	10100	10100	10100	10100	10100	10100	10100	10100	10100	10100	10100	10100	10100	10100	10100	10100
				10100	10100	10100	10100	10100	10100	10100	10100	10100	10100	10100	10100	10100	10100	10100	10100	10100	10100
				10100	10100	10100	10100	10100	10100	10100	10100	10100	10100	10100	10100	10100	10100	10100	10100	10100	10100
				10100	10100	10100	10100	10100	10100	10100	10100	10100	10100	10100	10100	10100	10100	10100	10100	10100	10100
				10100	10100	10100	10100	10100	10100	10100	10100	10100	10100	10100	10100	10100	10100	10100	10100	10100	10100
				10100	10100	10100	10100	10100	10100	10100	10100	10100	10100	10100	10100	10100	10100	10100	10100	10100	10100
				10100	10100	10100	10100	10100	10100	10100	10100	10100	10100	10100	10100	10100	10100	10100	10100	10100	10100
				10100	10100	10100	10100	10100	10100	10100	10100	10100	10100	10100	10100	10100	10100	10100	10100	10100	10100
				10100	10100	10100	10100	10100	10100	10100	10100	10100	10100	10100	10100	10100	10100	10100	10100	10100	10100
				10100	10100	10100	10100	10100	10100	10100	10100	10100	10100	10100	10100	10100	10100	10100	10100	10100	10100
				10100	10100	10100	10100	10100	10100	10100	10100	10100	10100	10100	10100	10100	10100	10100	10100	10100	10100
				10100	10100	10100	10100	10100	10100	10100	10100	10100	10100	10100	10100	10100	10100	10100	10100	10100	10100
				10100	10100	10100	10100	10100	10100	10100	10100	10100	10100	10100	10100	10100	10100	10100	10100	10100	10100
				10100	10100	10100	10100	10100	10100	10100	10100	10100	10100	10100	10100	10100	10100	10100	10100	10100	10100
				10100	10100	10100	10100	10100	10100	10100	10100	10100	10100	10100	10100	10100	10100	10100	10100	10100	10100
				10100	10100	10100	10100	10100	10100	10100	10100	10100	10100	10100	10100	10100	10100	10100	10100	10100	10100
				10100	10100	10100	10100	10100	10100	10100	10100	10100	10100	10100	10100	10100	10100	10100	10100	10100	10100
				10100	10100	10100	10100	10100	10100	10100	10100	10100	10100	10100	10100	10100	10100	10100	10100	10100	10100
				10100	10100	10100	10100	10100	10100	10100	10100	10100	10100	10100	10100	10100	10100	10100	10100	10100	10100
				10100	10100	10100	10100	10100	10100	10100	10100	10100	10100	10100	10100	10100	10100	10100	10100	10100	10100
				10100	10100	10100	10100	10100	10100	10100	10100	10100	10100	10100	10100	10100	10100	10100	10100	10100	10100
				10100	10100	10100	10100	10100	10100	10100	10100	10100	10100	10100	10100	10100	10100	10100	10100	10100	10100
				10100	10100	10100	10100	10100	10100	10100	10100	10100	10100	10100	10100	10100	10100	10100	10100	10100	10100
				10100	10100	10100	10100	10100	10100	10100	10100	10100	10100	10100	10100	10100	10100	10100	10100	10100	10100
				10100	10100	10100	10100	10100	10100	10100	10100	10100	10100	10100	10100	10100	10100	10100	10100	10100	10100
				10100	10100	10100	10100	10100	10100	10100	10100	10100	10100	10100	10100	10100	10100	10100	10100	10100	10100
				10100	10100	10100	10100	10100	10100	10100	10100	10100	10100	10100	10100	10100	10100	10100	10100	10100	10100
				10100	10100	10100	10100	10100	10100	10100	10100	10100	10100	10100	10100	10100	10100	10100	10100	10100	10100
				10100	10100	10100	10100	10100	10100	10100	10100	10100	10100	10100	10100	10100	10100	10100	10100	10100	10100
				10100	10100	10100	10100	10100	10100	10100	10100	10100	10100	10100	10100	10100	10100	10100	10100	10100	10100
				>;

			PS_Config_Lmt_Open_Rawdata_P = <
				65535	3123	3097	3100	3070	3034	2989	2932	2855	2877	2926	2983	3031	3067	3098	3074	3125	65535
				3098	3122	3102	3077	3056	3034	3011	2986	2946	2962	2988	3010	3032	3053	3074	3101	3122	3073
				3109	3119	3102	3076	3053	3034	3011	2988	2943	2962	2992	3013	3032	3053	3073	3097	3116	3080
				3105	3116	3097	3073	3052	3030	3010	2985	2939	2936	2964	2985	3004	3024	3042	3069	3087	3058
				3129	3136	3118	3093	3076	3053	3032	3011	2967	2965	2995	3016	3034	3052	3070	3093	3111	3086
				3109	3119	3098	3077	3058	3035	3016	2993	2948	3006	3037	3059	3076	3093	3109	3133	3153	3128
				3123	3130	3109	3087	3069	3046	3025	3006	2958	2964	2993	3014	3031	3049	3067	3090	3109	3088
				3135	3143	3125	3104	3084	3063	3045	3021	2976	2904	2932	2954	2972	2992	3009	3031	3055	3034
				3121	3123	3102	3081	3065	3044	3024	2996	2957	2932	2957	2976	2999	3017	3035	3055	3079	3067
				3143	3149	3129	3109	3090	3069	3046	3020	2981	2944	2971	2993	3010	3032	3052	3073	3095	3084
				3151	3156	3135	3116	3097	3074	3055	3030	2990	2971	2996	3017	3037	3056	3076	3097	3122	3112
				3144	3149	3130	3108	3090	3066	3046	3018	2981	2947	2972	2996	3013	3035	3055	3076	3100	3090
				3129	3137	3116	3094	3074	3053	3032	3011	2969	2974	2999	3024	3039	3060	3081	3100	3123	3115
				3144	3144	3122	3100	3079	3058	3038	3016	2974	2974	3003	3024	3044	3062	3080	3101	3123	3122
				3137	3142	3118	3098	3079	3059	3039	3016	2974	2989	3018	3039	3059	3077	3100	3119	3144	3143
				3156	3151	3130	3112	3091	3072	3053	3028	2986	2988	3016	3038	3056	3074	3094	3114	3135	3136
				3158	3156	3137	3119	3100	3080	3063	3039	2997	2999	3027	3051	3067	3087	3108	3126	3147	3144
				3163	3161	3139	3121	3102	3083	3065	3041	3000	2989	3017	3038	3056	3073	3093	3114	3136	3136
				3198	3196	3175	3156	3135	3114	3097	3072	3030	3020	3046	3070	3086	3105	3126	3147	3171	3170
				3209	3206	3184	3167	3144	3126	3109	3084	3042	3007	3035	3058	3076	3094	3115	3136	3160	3160
				3189	3185	3164	3146	3125	3108	3090	3066	3024	3009	3037	3058	3076	3097	3116	3133	3157	3158
				3207	3206	3184	3165	3144	3128	3109	3086	3045	3011	3039	3060	3077	3095	3118	3135	3158	3157
				3213	3205	3185	3168	3149	3128	3111	3088	3046	3030	3059	3080	3097	3119	3137	3154	3179	3184
				3154	3153	3133	3115	3094	3077	3060	3037	2996	3028	3056	3080	3097	3114	3133	3150	3177	3175
				3196	3195	3171	3153	3135	3116	3098	3074	3035	3010	3038	3059	3077	3095	3114	3132	3153	3157
				3254	3256	3235	3217	3200	3181	3164	3139	3098	3004	3031	3053	3073	3088	3111	3128	3151	3151
				3212	3213	3193	3178	3161	3143	3123	3100	3058	3024	3051	3073	3088	3109	3128	3149	3172	3177
				3282	3284	3266	3248	3231	3212	3195	3167	3125	3094	3122	3147	3167	3188	3206	3224	3248	3255
				3041	3291	3273	3259	3240	3220	3200	3174	3132	3100	3126	3150	3170	3189	3212	3227	3254	3011
				3039	3291	3272	3255	3235	3213	3193	3167	3125	3109	3133	3160	3181	3199	3219	3237	3259	3017
				2997	3254	3231	3217	3198	3178	3158	3132	3093	3122	3146	3171	3192	3209	3228	3247	3270	3031
				3094	3242	3280	3263	3244	3227	3209	3185	3154	3122	3142	3171	3195	3216	3240	3262	3233	3098
				>;

			PS_Config_Lmt_Open_Rawdata_N = <
				(-65535)	1339	1327	1328	1316	1300	1281	1256	1223	1233	1254	1279	1299	1315	1328	1318	1339	(-65535)
				1328	1338	1330	1319	1310	1300	1291	1280	1262	1270	1280	1290	1300	1309	1318	1329	1338	1317
				1333	1337	1330	1318	1309	1300	1291	1280	1261	1270	1282	1291	1300	1309	1317	1327	1336	1320
				1331	1336	1327	1317	1308	1298	1290	1279	1259	1258	1270	1279	1288	1296	1304	1315	1323	1310
				1341	1344	1336	1325	1318	1309	1300	1291	1271	1271	1283	1292	1300	1308	1316	1325	1333	1322
				1333	1337	1328	1319	1310	1301	1292	1283	1264	1288	1301	1311	1318	1325	1333	1343	1351	1340
				1339	1342	1333	1323	1315	1306	1297	1288	1268	1270	1283	1292	1299	1307	1315	1324	1333	1324
				1343	1347	1339	1330	1322	1313	1305	1295	1276	1244	1256	1266	1274	1282	1289	1299	1309	1300
				1337	1339	1330	1321	1313	1304	1296	1284	1267	1256	1267	1276	1285	1293	1301	1309	1319	1315
				1347	1349	1341	1333	1324	1315	1306	1294	1277	1262	1273	1283	1290	1300	1308	1317	1327	1322
				1351	1352	1343	1336	1327	1318	1309	1298	1282	1273	1284	1293	1301	1310	1318	1327	1338	1334
				1348	1349	1342	1332	1324	1314	1306	1294	1277	1263	1274	1284	1291	1301	1309	1318	1328	1324
				1341	1345	1336	1326	1318	1309	1300	1291	1273	1274	1285	1296	1303	1312	1321	1328	1339	1335
				1348	1348	1338	1328	1319	1310	1302	1292	1274	1274	1287	1296	1304	1312	1320	1329	1339	1338
				1345	1346	1336	1328	1319	1311	1303	1292	1274	1281	1294	1303	1311	1319	1328	1337	1348	1347
				1352	1351	1342	1334	1325	1316	1309	1298	1280	1280	1292	1302	1310	1318	1326	1334	1343	1344
				1354	1352	1345	1337	1328	1320	1313	1303	1285	1285	1297	1307	1315	1323	1332	1340	1349	1348
				1355	1355	1345	1337	1330	1321	1313	1303	1286	1281	1293	1302	1310	1317	1325	1334	1344	1344
				1370	1370	1361	1352	1343	1334	1327	1316	1298	1294	1306	1316	1322	1331	1340	1349	1359	1358
				1375	1374	1364	1357	1348	1340	1333	1322	1304	1289	1301	1310	1318	1326	1335	1344	1354	1354
				1367	1365	1356	1348	1339	1332	1324	1314	1296	1289	1301	1310	1318	1327	1336	1343	1353	1354
				1375	1374	1364	1357	1348	1340	1333	1322	1305	1291	1303	1312	1319	1327	1336	1343	1354	1353
				1377	1373	1365	1358	1349	1340	1333	1324	1306	1298	1311	1320	1327	1337	1345	1352	1363	1364
				1352	1351	1343	1335	1326	1319	1312	1301	1284	1298	1310	1320	1327	1334	1343	1350	1361	1361
				1370	1369	1359	1351	1343	1336	1328	1318	1301	1290	1302	1311	1319	1327	1334	1342	1351	1353
				1394	1396	1387	1379	1372	1363	1356	1345	1328	1288	1299	1309	1317	1324	1333	1340	1351	1351
				1376	1377	1369	1362	1355	1347	1339	1328	1310	1296	1307	1317	1324	1333	1340	1349	1360	1361
				1406	1408	1400	1392	1385	1376	1369	1357	1339	1326	1338	1349	1357	1366	1374	1382	1392	1395
				1303	1411	1403	1397	1388	1380	1372	1360	1342	1328	1340	1350	1358	1367	1376	1383	1394	1291
				1303	1411	1402	1395	1387	1377	1369	1357	1339	1333	1343	1354	1363	1371	1379	1387	1397	1293
				1285	1394	1385	1379	1370	1362	1354	1342	1325	1338	1348	1359	1368	1375	1384	1391	1402	1299
				1326	1390	1406	1399	1390	1383	1375	1365	1352	1338	1346	1359	1369	1378	1388	1398	1385	1328
				>;

			PS_Config_Lmt_FW_Rawdata_P = <
				65535	1116	1124	1120	1107	1120	1123	1119	1119	1124	1126	1106	1119	1126	1121	1120	1119	65535
				1117	1121	1123	1128	1120	1126	1131	1126	1123	1124	1128	1128	1131	1134	1119	1120	1124	1119
				1119	1131	1120	1120	1124	1126	1121	1117	1120	1112	1117	1113	1117	1114	1116	1124	1119	1133
				1116	1126	1121	1119	1117	1124	1116	1126	1121	1120	1116	1120	1121	1123	1117	1128	1114	1117
				1119	1127	1120	1112	1110	1123	1112	1121	1109	1114	1119	1109	1116	1113	1112	1121	1119	1114
				1114	1127	1112	1124	1128	1124	1128	1131	1126	1116	1114	1114	1114	1117	1117	1120	1116	1119
				1119	1114	1124	1120	1127	1128	1124	1112	1124	1112	1112	1112	1107	1114	1112	1123	1126	1117
				1128	1114	1117	1117	1113	1112	1113	1116	1117	1123	1123	1126	1116	1116	1116	1114	1128	1117
				1120	1120	1126	1120	1123	1117	1119	1119	1117	1119	1116	1113	1116	1117	1121	1120	1123	1123
				1123	1120	1119	1119	1120	1127	1126	1127	1121	1119	1114	1113	1116	1123	1120	1123	1121	1120
				1119	1124	1120	1126	1121	1121	1121	1119	1114	1123	1123	1133	1134	1128	1128	1121	1123	1119
				1120	1123	1113	1117	1116	1120	1112	1116	1116	1109	1116	1120	1117	1117	1124	1126	1121	1123
				1119	1119	1124	1128	1121	1130	1126	1123	1110	1121	1113	1116	1114	1113	1116	1124	1109	1114
				1123	1117	1116	1123	1126	1123	1121	1124	1117	1120	1120	1116	1120	1121	1121	1120	1126	1120
				1126	1120	1117	1120	1126	1127	1112	1128	1120	1120	1119	1117	1126	1119	1123	1110	1120	1123
				1116	1120	1114	1116	1119	1123	1112	1113	1117	1127	1117	1121	1117	1119	1119	1119	1127	1124
				1119	1126	1121	1119	1123	1123	1127	1117	1117	1116	1121	1117	1121	1116	1117	1121	1116	1113
				1127	1124	1121	1117	1114	1117	1117	1116	1123	1124	1110	1114	1116	1117	1116	1107	1120	1121
				1114	1117	1114	1121	1120	1121	1110	1126	1116	1121	1110	1116	1117	1113	1114	1120	1116	1126
				1123	1107	1109	1124	1127	1126	1124	1126	1119	1127	1109	1109	1113	1114	1112	1120	1112	1127
				1123	1114	1123	1123	1119	1116	1121	1117	1126	1116	1126	1128	1113	1126	1113	1117	1117	1119
				1119	1119	1117	1114	1116	1116	1123	1126	1119	1123	1121	1123	1121	1130	1117	1120	1105	1113
				1119	1120	1116	1116	1123	1123	1123	1121	1116	1130	1114	1112	1113	1109	1110	1123	1113	1116
				1120	1116	1119	1119	1105	1116	1110	1110	1124	1124	1119	1117	1117	1117	1121	1131	1114	1114
				1126	1113	1124	1124	1119	1119	1116	1114	1121	1110	1123	1124	1124	1123	1127	1107	1113	1120
				1123	1119	1127	1114	1113	1114	1114	1113	1124	1112	1121	1112	1119	1123	1116	1113	1119	1114
				1120	1128	1119	1124	1119	1124	1133	1124	1121	1126	1120	1119	1120	1120	1121	1127	1119	1126
				1123	1121	1116	1131	1120	1120	1121	1114	1116	1119	1109	1117	1124	1128	1127	1123	1124	1121
				1127	1121	1120	1124	1127	1126	1119	1120	1117	1119	1117	1114	1119	1117	1121	1114	1121	1116
				1117	1123	1117	1117	1116	1120	1117	1116	1121	1131	1109	1114	1114	1110	1110	1120	1119	1119
				1119	1128	1107	1114	1121	1126	1119	1116	1117	1117	1121	1123	1126	1123	1119	1120	1120	1113
				1123	1117	1120	1114	1116	1120	1112	1121	1119	1120	1133	1138	1120	1126	1128	1103	1114	1121
				>;

			PS_Config_Lmt_FW_Rawdata_N = <
				(-65535)	478	482	480	475	480	481	479	479	482	482	474	479	482	481	480	479	(-65535)
				479	481	481	484	480	482	485	482	481	482	484	484	485	486	479	480	482	479
				479	485	480	480	482	482	481	479	480	476	479	477	479	478	478	482	479	485
				478	482	481	479	479	482	478	482	481	480	478	480	481	481	479	484	478	479
				479	483	480	476	476	481	476	481	475	478	479	475	478	477	476	481	479	478
				478	483	476	482	484	482	484	485	482	478	478	478	478	479	479	480	478	479
				479	478	482	480	483	484	482	476	482	476	476	476	475	478	476	481	482	479
				484	478	479	479	477	476	477	478	479	481	481	482	478	478	478	478	484	479
				480	480	482	480	481	479	479	479	479	479	478	477	478	479	481	480	481	481
				481	480	479	479	480	483	482	483	481	479	478	477	478	481	480	481	481	480
				479	482	480	482	481	481	481	479	478	481	481	485	486	484	484	481	481	479
				480	481	477	479	478	480	476	478	478	475	478	480	479	479	482	482	481	481
				479	479	482	484	481	484	482	481	476	481	477	478	478	477	478	482	475	478
				481	479	478	481	482	481	481	482	479	480	480	478	480	481	481	480	482	480
				482	480	479	480	482	483	476	484	480	480	479	479	482	479	481	476	480	481
				478	480	478	478	479	481	476	477	479	483	479	481	479	479	479	479	483	482
				479	482	481	479	481	481	483	479	479	478	481	479	481	478	479	481	478	477
				483	482	481	479	478	479	479	478	481	482	476	478	478	479	478	475	480	481
				478	479	478	481	480	481	476	482	478	481	476	478	479	477	478	480	478	482
				481	475	475	482	483	482	482	482	479	483	475	475	477	478	476	480	476	483
				481	478	481	481	479	478	481	479	482	478	482	484	477	482	477	479	479	479
				479	479	479	478	478	478	481	482	479	481	481	481	481	484	479	480	473	477
				479	480	478	478	481	481	481	481	478	484	478	476	477	475	476	481	477	478
				480	478	479	479	473	478	476	476	482	482	479	479	479	479	481	485	478	478
				482	477	482	482	479	479	478	478	481	476	481	482	482	481	483	475	477	480
				481	479	483	478	477	478	478	477	482	476	481	476	479	481	478	477	479	478
				480	484	479	482	479	482	485	482	481	482	480	479	480	480	481	483	479	482
				481	481	478	485	480	480	481	478	478	479	475	479	482	484	483	481	482	481
				483	481	480	482	483	482	479	480	479	479	479	478	479	479	481	478	481	478
				479	481	479	479	478	480	479	478	481	485	475	478	478	476	476	480	479	479
				479	484	475	478	481	482	479	478	479	479	481	481	482	481	479	480	480	477
				481	479	480	478	478	480	476	481	479	480	485	488	480	482	484	473	478	481
				>;

			PS_Config_Lmt_FW_CC_P = <
				65535	156	157	152	150	149	149	148	144	144	148	149	149	150	152	157	156	65535
				156	153	148	144	142	142	142	142	142	142	142	142	142	142	142	148	152	155
				157	152	148	144	144	144	144	144	144	144	144	144	144	144	144	148	153	156
				156	150	148	144	144	142	144	144	142	142	144	142	142	142	142	146	152	155
				157	153	148	144	144	144	144	144	144	144	145	144	144	144	144	148	152	157
				155	152	148	144	144	144	144	144	144	145	145	145	145	145	145	149	153	156
				156	152	148	144	144	144	144	144	144	144	145	145	144	144	144	148	152	156
				156	152	146	144	144	144	144	144	144	144	144	144	144	144	144	146	150	155
				156	152	146	144	144	144	144	144	144	144	142	144	144	144	144	146	152	156
				155	150	146	144	144	144	144	144	144	144	142	142	142	144	144	146	149	155
				155	150	146	144	144	144	144	144	144	145	145	144	144	144	144	146	150	156
				155	150	146	144	144	144	144	144	144	145	144	144	144	144	144	146	150	155
				155	150	146	144	144	144	144	144	145	145	145	145	144	145	145	146	150	155
				156	150	146	144	144	144	144	144	144	144	144	144	144	144	144	145	150	156
				155	150	145	144	144	144	144	144	145	145	144	144	144	144	144	146	150	155
				156	150	146	145	145	145	145	145	145	145	145	145	145	145	145	146	150	156
				157	155	149	146	146	146	146	146	148	148	148	148	148	148	148	149	155	157
				157	153	148	146	146	146	146	146	146	148	146	146	146	146	146	148	153	157
				157	155	149	146	146	146	148	146	148	148	146	148	146	148	148	149	153	157
				159	155	149	148	148	148	148	148	149	148	146	146	146	146	146	148	153	156
				157	155	149	148	148	148	148	148	149	148	146	146	148	146	148	149	153	157
				157	153	149	148	148	148	146	146	148	148	146	148	148	148	148	149	155	156
				159	155	149	148	148	148	148	148	149	148	146	146	146	146	148	148	153	157
				156	153	148	146	146	146	146	146	148	148	146	146	146	148	148	148	153	156
				156	153	148	146	146	146	146	146	148	148	146	146	146	146	146	148	153	156
				157	155	149	148	148	148	148	148	149	148	146	146	146	146	146	148	152	156
				157	155	149	149	148	148	148	148	149	148	146	146	146	146	148	148	153	157
				159	155	149	149	148	148	148	148	149	149	148	148	148	148	148	149	155	157
				153	155	149	148	148	148	148	146	149	150	148	149	149	149	149	149	155	156
				155	155	149	149	149	148	148	148	150	150	148	148	148	148	148	149	153	155
				155	155	149	149	148	148	148	148	150	150	148	148	148	148	148	149	153	153
				156	155	150	149	149	149	149	149	150	152	149	149	149	149	149	150	155	156
				>;

			PS_Config_Lmt_FW_CC_N = <
				(-65535)	70	71	68	68	67	67	66	64	64	66	67	67	68	68	71	70	(-65535)
				70	69	66	64	64	64	64	64	64	64	64	64	64	64	64	66	68	69
				71	68	66	64	64	64	64	64	64	64	64	64	64	64	64	66	69	70
				70	68	66	64	64	64	64	64	64	64	64	64	64	64	64	66	68	69
				71	69	66	64	64	64	64	64	64	64	65	64	64	64	64	66	68	71
				69	68	66	64	64	64	64	64	64	65	65	65	65	65	65	67	69	70
				70	68	66	64	64	64	64	64	64	64	65	65	64	64	64	66	68	70
				70	68	66	64	64	64	64	64	64	64	64	64	64	64	64	66	68	69
				70	68	66	64	64	64	64	64	64	64	64	64	64	64	64	66	68	70
				69	68	66	64	64	64	64	64	64	64	64	64	64	64	64	66	67	69
				69	68	66	64	64	64	64	64	64	65	65	64	64	64	64	66	68	70
				69	68	66	64	64	64	64	64	64	65	64	64	64	64	64	66	68	69
				69	68	66	64	64	64	64	64	65	65	65	65	64	65	65	66	68	69
				70	68	66	64	64	64	64	64	64	64	64	64	64	64	64	65	68	70
				69	68	65	64	64	64	64	64	65	65	64	64	64	64	64	66	68	69
				70	68	66	65	65	65	65	65	65	65	65	65	65	65	65	66	68	70
				71	69	67	66	66	66	66	66	66	66	66	66	66	66	66	67	69	71
				71	69	66	66	66	66	66	66	66	66	66	66	66	66	66	66	69	71
				71	69	67	66	66	66	66	66	66	66	66	66	66	66	66	67	69	71
				71	69	67	66	66	66	66	66	67	66	66	66	66	66	66	66	69	70
				71	69	67	66	66	66	66	66	67	66	66	66	66	66	66	67	69	71
				71	69	67	66	66	66	66	66	66	66	66	66	66	66	66	67	69	70
				71	69	67	66	66	66	66	66	67	66	66	66	66	66	66	66	69	71
				70	69	66	66	66	66	66	66	66	66	66	66	66	66	66	66	69	70
				70	69	66	66	66	66	66	66	66	66	66	66	66	66	66	66	69	70
				71	69	67	66	66	66	66	66	67	66	66	66	66	66	66	66	68	70
				71	69	67	67	66	66	66	66	67	66	66	66	66	66	66	66	69	71
				71	69	67	67	66	66	66	66	67	67	66	66	66	66	66	67	69	71
				69	69	67	66	66	66	66	66	67	68	66	67	67	67	67	67	69	70
				69	69	67	67	67	66	66	66	68	68	66	66	66	66	66	67	69	69
				69	69	67	67	66	66	66	66	68	68	66	66	66	66	66	67	69	69
				70	69	68	67	67	67	67	67	68	68	67	67	67	67	67	68	69	70
				>;

			PS_Config_Lmt_FW_Diff_P = <
				65535	50	50	50	50	50	50	50	50	50	50	50	50	50	50	50	50	65535
				50	50	50	50	50	50	50	50	50	50	50	50	50	50	50	50	50	50
				50	50	50	50	50	50	50	50	50	50	50	50	50	50	50	50	50	50
				50	50	50	50	50	50	50	50	50	50	50	50	50	50	50	50	50	50
				50	50	50	50	50	50	50	50	50	50	50	50	50	50	50	50	50	50
				50	50	50	50	50	50	50	50	50	50	50	50	50	50	50	50	50	50
				50	50	50	50	50	50	50	50	50	50	50	50	50	50	50	50	50	50
				50	50	50	50	50	50	50	50	50	50	50	50	50	50	50	50	50	50
				50	50	50	50	50	50	50	50	50	50	50	50	50	50	50	50	50	50
				50	50	50	50	50	50	50	50	50	50	50	50	50	50	50	50	50	50
				50	50	50	50	50	50	50	50	50	50	50	50	50	50	50	50	50	50
				50	50	50	50	50	50	50	50	50	50	50	50	50	50	50	50	50	50
				50	50	50	50	50	50	50	50	50	50	50	50	50	50	50	50	50	50
				50	50	50	50	50	50	50	50	50	50	50	50	50	50	50	50	50	50
				50	50	50	50	50	50	50	50	50	50	50	50	50	50	50	50	50	50
				50	50	50	50	50	50	50	50	50	50	50	50	50	50	50	50	50	50
				50	50	50	50	50	50	50	50	50	50	50	50	50	50	50	50	50	50
				50	50	50	50	50	50	50	50	50	50	50	50	50	50	50	50	50	50
				50	50	50	50	50	50	50	50	50	50	50	50	50	50	50	50	50	50
				50	50	50	50	50	50	50	50	50	50	50	50	50	50	50	50	50	50
				50	50	50	50	50	50	50	50	50	50	50	50	50	50	50	50	50	50
				50	50	50	50	50	50	50	50	50	50	50	50	50	50	50	50	50	50
				50	50	50	50	50	50	50	50	50	50	50	50	50	50	50	50	50	50
				50	50	50	50	50	50	50	50	50	50	50	50	50	50	50	50	50	50
				50	50	50	50	50	50	50	50	50	50	50	50	50	50	50	50	50	50
				50	50	50	50	50	50	50	50	50	50	50	50	50	50	50	50	50	50
				50	50	50	50	50	50	50	50	50	50	50	50	50	50	50	50	50	50
				50	50	50	50	50	50	50	50	50	50	50	50	50	50	50	50	50	50
				50	50	50	50	50	50	50	50	50	50	50	50	50	50	50	50	50	50
				50	50	50	50	50	50	50	50	50	50	50	50	50	50	50	50	50	50
				50	50	50	50	50	50	50	50	50	50	50	50	50	50	50	50	50	50
				50	50	50	50	50	50	50	50	50	50	50	50	50	50	50	50	50	50
				>;

			PS_Config_Lmt_FW_Diff_N = <
				(-65535)	(-50)	(-50)	(-50)	(-50)	(-50)	(-50)	(-50)	(-50)	(-50)	(-50)	(-50)	(-50)	(-50)	(-50)	(-50)	(-50)	(-65535)
				(-50)	(-50)	(-50)	(-50)	(-50)	(-50)	(-50)	(-50)	(-50)	(-50)	(-50)	(-50)	(-50)	(-50)	(-50)	(-50)	(-50)	(-50)
				(-50)	(-50)	(-50)	(-50)	(-50)	(-50)	(-50)	(-50)	(-50)	(-50)	(-50)	(-50)	(-50)	(-50)	(-50)	(-50)	(-50)	(-50)
				(-50)	(-50)	(-50)	(-50)	(-50)	(-50)	(-50)	(-50)	(-50)	(-50)	(-50)	(-50)	(-50)	(-50)	(-50)	(-50)	(-50)	(-50)
				(-50)	(-50)	(-50)	(-50)	(-50)	(-50)	(-50)	(-50)	(-50)	(-50)	(-50)	(-50)	(-50)	(-50)	(-50)	(-50)	(-50)	(-50)
				(-50)	(-50)	(-50)	(-50)	(-50)	(-50)	(-50)	(-50)	(-50)	(-50)	(-50)	(-50)	(-50)	(-50)	(-50)	(-50)	(-50)	(-50)
				(-50)	(-50)	(-50)	(-50)	(-50)	(-50)	(-50)	(-50)	(-50)	(-50)	(-50)	(-50)	(-50)	(-50)	(-50)	(-50)	(-50)	(-50)
				(-50)	(-50)	(-50)	(-50)	(-50)	(-50)	(-50)	(-50)	(-50)	(-50)	(-50)	(-50)	(-50)	(-50)	(-50)	(-50)	(-50)	(-50)
				(-50)	(-50)	(-50)	(-50)	(-50)	(-50)	(-50)	(-50)	(-50)	(-50)	(-50)	(-50)	(-50)	(-50)	(-50)	(-50)	(-50)	(-50)
				(-50)	(-50)	(-50)	(-50)	(-50)	(-50)	(-50)	(-50)	(-50)	(-50)	(-50)	(-50)	(-50)	(-50)	(-50)	(-50)	(-50)	(-50)
				(-50)	(-50)	(-50)	(-50)	(-50)	(-50)	(-50)	(-50)	(-50)	(-50)	(-50)	(-50)	(-50)	(-50)	(-50)	(-50)	(-50)	(-50)
				(-50)	(-50)	(-50)	(-50)	(-50)	(-50)	(-50)	(-50)	(-50)	(-50)	(-50)	(-50)	(-50)	(-50)	(-50)	(-50)	(-50)	(-50)
				(-50)	(-50)	(-50)	(-50)	(-50)	(-50)	(-50)	(-50)	(-50)	(-50)	(-50)	(-50)	(-50)	(-50)	(-50)	(-50)	(-50)	(-50)
				(-50)	(-50)	(-50)	(-50)	(-50)	(-50)	(-50)	(-50)	(-50)	(-50)	(-50)	(-50)	(-50)	(-50)	(-50)	(-50)	(-50)	(-50)
				(-50)	(-50)	(-50)	(-50)	(-50)	(-50)	(-50)	(-50)	(-50)	(-50)	(-50)	(-50)	(-50)	(-50)	(-50)	(-50)	(-50)	(-50)
				(-50)	(-50)	(-50)	(-50)	(-50)	(-50)	(-50)	(-50)	(-50)	(-50)	(-50)	(-50)	(-50)	(-50)	(-50)	(-50)	(-50)	(-50)
				(-50)	(-50)	(-50)	(-50)	(-50)	(-50)	(-50)	(-50)	(-50)	(-50)	(-50)	(-50)	(-50)	(-50)	(-50)	(-50)	(-50)	(-50)
				(-50)	(-50)	(-50)	(-50)	(-50)	(-50)	(-50)	(-50)	(-50)	(-50)	(-50)	(-50)	(-50)	(-50)	(-50)	(-50)	(-50)	(-50)
				(-50)	(-50)	(-50)	(-50)	(-50)	(-50)	(-50)	(-50)	(-50)	(-50)	(-50)	(-50)	(-50)	(-50)	(-50)	(-50)	(-50)	(-50)
				(-50)	(-50)	(-50)	(-50)	(-50)	(-50)	(-50)	(-50)	(-50)	(-50)	(-50)	(-50)	(-50)	(-50)	(-50)	(-50)	(-50)	(-50)
				(-50)	(-50)	(-50)	(-50)	(-50)	(-50)	(-50)	(-50)	(-50)	(-50)	(-50)	(-50)	(-50)	(-50)	(-50)	(-50)	(-50)	(-50)
				(-50)	(-50)	(-50)	(-50)	(-50)	(-50)	(-50)	(-50)	(-50)	(-50)	(-50)	(-50)	(-50)	(-50)	(-50)	(-50)	(-50)	(-50)
				(-50)	(-50)	(-50)	(-50)	(-50)	(-50)	(-50)	(-50)	(-50)	(-50)	(-50)	(-50)	(-50)	(-50)	(-50)	(-50)	(-50)	(-50)
				(-50)	(-50)	(-50)	(-50)	(-50)	(-50)	(-50)	(-50)	(-50)	(-50)	(-50)	(-50)	(-50)	(-50)	(-50)	(-50)	(-50)	(-50)
				(-50)	(-50)	(-50)	(-50)	(-50)	(-50)	(-50)	(-50)	(-50)	(-50)	(-50)	(-50)	(-50)	(-50)	(-50)	(-50)	(-50)	(-50)
				(-50)	(-50)	(-50)	(-50)	(-50)	(-50)	(-50)	(-50)	(-50)	(-50)	(-50)	(-50)	(-50)	(-50)	(-50)	(-50)	(-50)	(-50)
				(-50)	(-50)	(-50)	(-50)	(-50)	(-50)	(-50)	(-50)	(-50)	(-50)	(-50)	(-50)	(-50)	(-50)	(-50)	(-50)	(-50)	(-50)
				(-50)	(-50)	(-50)	(-50)	(-50)	(-50)	(-50)	(-50)	(-50)	(-50)	(-50)	(-50)	(-50)	(-50)	(-50)	(-50)	(-50)	(-50)
				(-50)	(-50)	(-50)	(-50)	(-50)	(-50)	(-50)	(-50)	(-50)	(-50)	(-50)	(-50)	(-50)	(-50)	(-50)	(-50)	(-50)	(-50)
				(-50)	(-50)	(-50)	(-50)	(-50)	(-50)	(-50)	(-50)	(-50)	(-50)	(-50)	(-50)	(-50)	(-50)	(-50)	(-50)	(-50)	(-50)
				(-50)	(-50)	(-50)	(-50)	(-50)	(-50)	(-50)	(-50)	(-50)	(-50)	(-50)	(-50)	(-50)	(-50)	(-50)	(-50)	(-50)	(-50)
				(-50)	(-50)	(-50)	(-50)	(-50)	(-50)	(-50)	(-50)	(-50)	(-50)	(-50)	(-50)	(-50)	(-50)	(-50)	(-50)	(-50)	(-50)
				>;

			PS_Config_Lmt_Doze_FW_Rawdata_P = <
				620 620
				620 620
				620 620
				620 620
				620 620
				620 620
				620 620
				620 620
				620 620
				620 620
				620 620
				620 620
				620 620
				620 620
				620 620
				620 620
				620 620
				620 620
				620 620
				620 620
				620 620
				620 620
				620 620
				620 620
				620 620
				620 620
				620 620
				620 620
				620 620
				620 620
				620 620
				620 620
				>;

			PS_Config_Lmt_Doze_FW_Rawdata_N = <
				180 180
				180 180
				180 180
				180 180
				180 180
				180 180
				180 180
				180 180
				180 180
				180 180
				180 180
				180 180
				180 180
				180 180
				180 180
				180 180
				180 180
				180 180
				180 180
				180 180
				180 180
				180 180
				180 180
				180 180
				180 180
				180 180
				180 180
				180 180
				180 180
				180 180
				180 180
				180 180
				>;

			PS_Config_Lmt_Doze_FW_CC_P = <
				245 245
				245 245
				245 245
				245 245
				245 245
				245 245
				245 245
				245 245
				245 245
				245 245
				245 245
				245 245
				245 245
				245 245
				245 245
				245 245
				245 245
				245 245
				245 245
				245 245
				245 245
				245 245
				245 245
				245 245
				245 245
				245 245
				245 245
				245 245
				245 245
				245 245
				245 245
				245 245
				>;

			PS_Config_Lmt_Doze_FW_CC_N = <
				0 0
				0 0
				0 0
				0 0
				0 0
				0 0
				0 0
				0 0
				0 0
				0 0
				0 0
				0 0
				0 0
				0 0
				0 0
				0 0
				0 0
				0 0
				0 0
				0 0
				0 0
				0 0
				0 0
				0 0
				0 0
				0 0
				0 0
				0 0
				0 0
				0 0
				0 0
				0 0
				>;

			PS_Config_Lmt_Doze_FW_Diff_P = <
				160 160
				160 160
				160 160
				160 160
				160 160
				160 160
				160 160
				160 160
				160 160
				160 160
				160 160
				160 160
				160 160
				160 160
				160 160
				160 160
				160 160
				160 160
				160 160
				160 160
				160 160
				160 160
				160 160
				160 160
				160 160
				160 160
				160 160
				160 160
				160 160
				160 160
				160 160
				160 160
				>;

			PS_Config_Lmt_Doze_FW_Diff_N = <
				(-160) (-160)
				(-160) (-160)
				(-160) (-160)
				(-160) (-160)
				(-160) (-160)
				(-160) (-160)
				(-160) (-160)
				(-160) (-160)
				(-160) (-160)
				(-160) (-160)
				(-160) (-160)
				(-160) (-160)
				(-160) (-160)
				(-160) (-160)
				(-160) (-160)
				(-160) (-160)
				(-160) (-160)
				(-160) (-160)
				(-160) (-160)
				(-160) (-160)
				(-160) (-160)
				(-160) (-160)
				(-160) (-160)
				(-160) (-160)
				(-160) (-160)
				(-160) (-160)
				(-160) (-160)
				(-160) (-160)
				(-160) (-160)
				(-160) (-160)
				(-160) (-160)
				(-160) (-160)
				>;

			PS_Config_Diff_Test_Frame = <50>;
		};
	};
};

&pio {
	nvt_pins_eint_as_int: eint1touch@0 {
		pins_cmd_dat {
			pinmux = <PINMUX_GPIO14__FUNC_GPIO14>;
			input-enable;
		};
	};
	nvt_pins_rst_output: rstoutput0 {
		pins_cmd_dat {
			pinmux = <PINMUX_GPIO15__FUNC_GPIO15>;
			output-low;
		};
	};
	nvt_spi_mode: spimode_default {
		pins_cmd_dat {
			pinmux = <PINMUX_GPIO12__FUNC_SPI4_MI>,
				<PINMUX_GPIO13__FUNC_SPI4_MO>,
				<PINMUX_GPIO97__FUNC_SPI4_CLK>,
				<PINMUX_GPIO98__FUNC_SPI4_CSB>;
			drive-strength = <6>;
		};
	};
	nvt_spi_disable: spimode_disable {
		pins_cmd_dat {
			pinmux = <PINMUX_GPIO12__FUNC_GPIO12>,
				<PINMUX_GPIO13__FUNC_GPIO13>,
				<PINMUX_GPIO97__FUNC_GPIO97>,
				<PINMUX_GPIO98__FUNC_GPIO98>;
			output-low;
		};
	};
};
